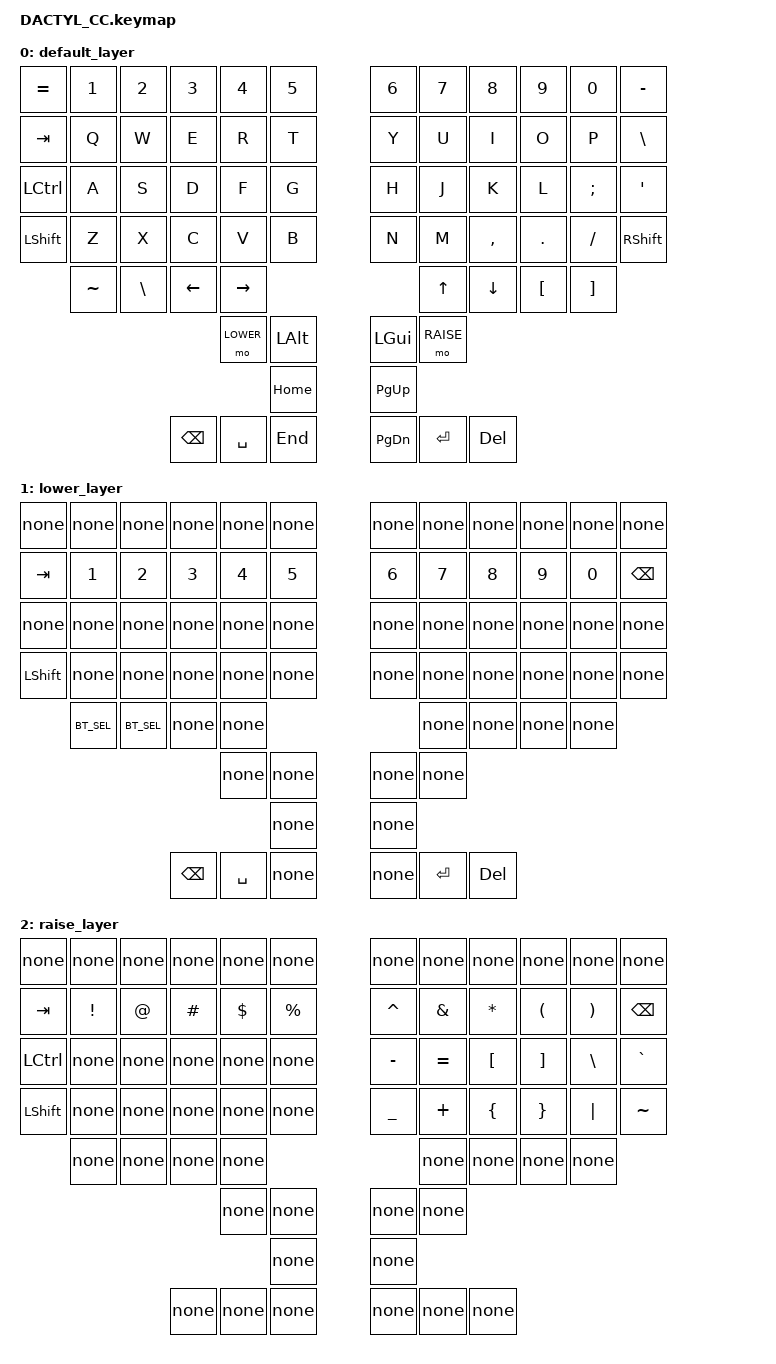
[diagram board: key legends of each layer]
#include <behaviors.dtsi>
#include <dt-bindings/zmk/keys.h>
#define DEFAULT 0
#define LOWER 1
#define RAISE 2

/ {
    keymap {
        compatible = "zmk,keymap";

        default_layer {
            bindings = <
    &kp EQUAL  &kp N1    &kp N2   &kp N3    &kp N4    &kp N5              &kp N6    &kp N7     &kp N8    &kp N9    &kp N0   &kp MINUS
    &kp TAB    &kp Q     &kp W    &kp E     &kp R     &kp T               &kp Y     &kp U      &kp I     &kp O     &kp P    &kp BSLH
    &kp LCTRL  &kp A     &kp S    &kp D     &kp F     &kp G               &kp H     &kp J      &kp K     &kp L     &kp SEMI &kp APOS
    &kp LSHIFT &kp Z     &kp X    &kp C     &kp V     &kp B               &kp N     &kp M      &kp COMMA &kp DOT   &kp FSLH &kp RSHIFT
               &kp TILDE &kp BSLH &kp LEFT  &kp RIGHT                               &kp UP     &kp DOWN  &kp LBKT  &kp RBKT  
                                            &mo LOWER &kp LALT            &kp LGUI  &mo RAISE         
                                                      &kp HOME            &kp PG_UP
                                  &kp BSPC  &kp SPACE &kp END             &kp PG_DN &kp RETURN &kp DELETE
            >;
        };
        
        lower_layer {
            bindings = <
    &kp none   &kp none     &kp none     &kp none  &kp none  &kp none                      &kp none    &kp none   &kp none   &kp none   &kp none  &kp none
    &kp TAB    &kp N1       &kp N2       &kp N3    &kp N4    &kp N5                        &kp N6      &kp N7     &kp N8     &kp N9     &kp N0    &kp BSPC
    &kp none   &kp none     &kp none     &kp none  &kp none  &kp none                      &kp none    &kp none   &kp none   &kp none   &kp none  &kp none
    &kp LSHIFT &kp none     &kp none     &kp none  &kp none  &kp none                      &kp none    &kp none   &kp none   &kp none   &kp none  &kp none
               &kp BT_SEL 0 &kp BT_SEL 1 &kp none  &kp none                                            &kp none   &kp none   &kp none   &kp none  
                                                   &kp none  &kp none                      &kp none    &kp none         
                                                             &kp none                      &kp none
                                        &kp BSPC  &kp SPACE  &kp none                      &kp none    &kp RETURN &kp DELETE
            >;
        };
        
        raise_layer {
            bindings = <
    &kp none   &kp none   &kp none   &kp none  &kp none  &kp none                      &kp none     &kp none   &kp none   &kp none   &kp none  &kp none
    &kp TAB    &kp EXCL   &kp AT     &kp HASH  &kp DLLR  &kp PRCNT                     &kp CARET    &kp AMPS   &kp STAR   &kp LPAR   &kp RPAR  &kp BSPC
    &kp LCTRL  &kp none   &kp none   &kp none  &kp none  &kp none                      &kp MINUS    &kp EQUAL  &kp LBKT   &kp RBKT   &kp BSLH  &kp GRAVE
    &kp LSHIFT &kp none   &kp none   &kp none  &kp none  &kp none                      &kp UNDER    &kp PLUS   &kp LBRC   &kp RBRC   &kp PIPE  &kp TILDE
               &kp none   &kp none   &kp none  &kp none                                             &kp none   &kp none   &kp none   &kp none  
                                               &kp none  &kp none                      &kp none     &kp none         
                                                         &kp none                      &kp none
                                     &kp none  &kp none  &kp none                      &kp none &kp none &kp none
            >;
        };        
    };
};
